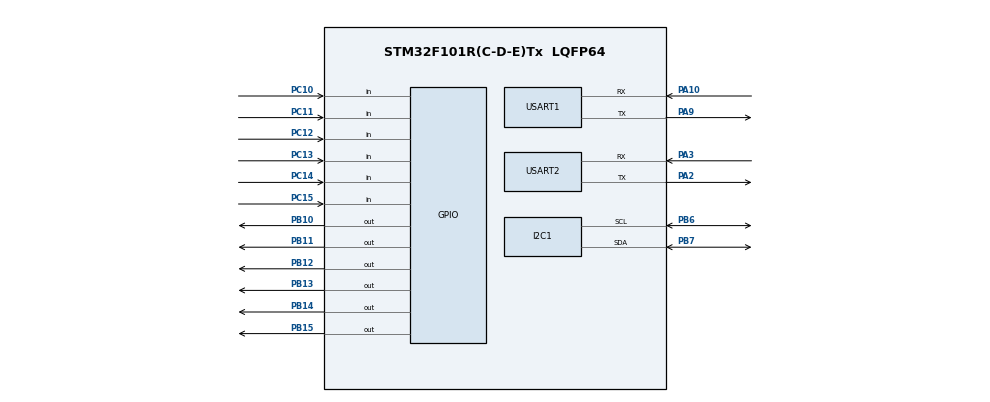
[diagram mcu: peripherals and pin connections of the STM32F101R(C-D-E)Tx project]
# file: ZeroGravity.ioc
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Mcu.Family=STM32F1
PD1-OSC_OUT.Mode=HSE-External-Oscillator
PA10.Mode=Asynchronous
PC10.Signal=GPIO_Input
PC11.Signal=GPIO_Input
PC12.Signal=GPIO_Input
PC13-TAMPER-RTC.Signal=GPIO_Input
PD0-OSC_IN.Signal=RCC_OSC_IN
PC14-OSC32_IN.Signal=GPIO_Input
PB11.Signal=GPIO_Output
PB15.Signal=GPIO_Output
PB13.Signal=GPIO_Output
ProjectManager.StackSize=0x400
PD1-OSC_OUT.Signal=RCC_OSC_OUT
PA13.Signal=SYS_JTMS-SWDIO
PA3.Mode=Asynchronous
PA9.Mode=Asynchronous
ProjectManager.TargetToolchain=STM32CubeIDE
PA9.Signal=USART1_TX
PB6.Signal=I2C1_SCL
PB6.Mode=I2C
PC15-OSC32_OUT.Signal=GPIO_Input
PB10.Signal=GPIO_Output
PD0-OSC_IN.Mode=HSE-External-Oscillator
PB14.Signal=GPIO_Output
board=custom
RCC.APB2Freq_Value=8000000
PA14.Mode=Serial_Wire
PB7.Signal=I2C1_SDA
PA13.Mode=Serial_Wire
Mcu.Name=STM32F101R(C-D-E)Tx
PA2.Signal=USART2_TX
Mcu.Package=LQFP64
USART2.VirtualMode=VM_ASYNC
USART1.VirtualMode=VM_ASYNC
PB7.Mode=I2C
PA10.Signal=USART1_RX
PA14.Signal=SYS_JTCK-SWCLK
ProjectManager.HeapSize=0x200
NVIC.PriorityGroup=NVIC_PRIORITYGROUP_4
PA2.Mode=Asynchronous
RCC.APB1Freq_Value=8000000
PB12.Signal=GPIO_Output
PA3.Signal=USART2_RX

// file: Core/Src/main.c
/* USER CODE BEGIN Header */
/**
  ******************************************************************************
  * @file           : main.c
  * @brief          : Main program body
  ******************************************************************************
  * @attention
  *
  * <h2><center>&copy; Copyright (c) 2021 STMicroelectronics.
  * All rights reserved.</center></h2>
  *
  * This software component is licensed by ST under BSD 3-Clause license,
  * the "License"; You may not use this file except in compliance with the
  * License. You may obtain a copy of the License at:
  *                        opensource.org/licenses/BSD-3-Clause
  *
  ******************************************************************************
  */
/* USER CODE END Header */
#include "main.h"
#include "i2c.h"
#include "usart.h"
#include "gpio.h"

/* USER CODE BEGIN Includes */
#include "sh1106.h"
/* USER CODE END Includes */

void SystemClock_Config(void);

int main(void)
{

  /* MCU Configuration--------------------------------------------------------*/

  /* Reset of all peripherals, Initializes the Flash interface and the Systick. */
  HAL_Init();

  /* Configure the system clock */
  SystemClock_Config();

  /* Initialize all configured peripherals */
  MX_GPIO_Init();
  MX_I2C1_Init();
  MX_USART1_UART_Init();
  MX_USART2_UART_Init();
  /* USER CODE BEGIN 2 */
  sh1106_Init();
  /* USER CODE END 2 */

  /* Infinite loop */
  while (1)
  {

    /* USER CODE BEGIN 3 */
	  //sh1106_test();
	  printf("Serial Test\r\n");
	  HAL_Delay(100);
  }
  /* USER CODE END 3 */
}

void SystemClock_Config(void)
{
  RCC_OscInitTypeDef RCC_OscInitStruct = {0};
  RCC_ClkInitTypeDef RCC_ClkInitStruct = {0};

  /** Initializes the RCC Oscillators according to the specified parameters
  * in the RCC_OscInitTypeDef structure.
  */
  RCC_OscInitStruct.OscillatorType = RCC_OSCILLATORTYPE_HSI;
  RCC_OscInitStruct.HSIState = RCC_HSI_ON;
  RCC_OscInitStruct.HSICalibrationValue = RCC_HSICALIBRATION_DEFAULT;
  RCC_OscInitStruct.PLL.PLLState = RCC_PLL_NONE;
  if (HAL_RCC_OscConfig(&RCC_OscInitStruct) != HAL_OK)
  {
    Error_Handler();
  }
  /** Initializes the CPU, AHB and APB buses clocks
  */
  RCC_ClkInitStruct.ClockType = RCC_CLOCKTYPE_HCLK|RCC_CLOCKTYPE_SYSCLK
                              |RCC_CLOCKTYPE_PCLK1|RCC_CLOCKTYPE_PCLK2;
  RCC_ClkInitStruct.SYSCLKSource = RCC_SYSCLKSOURCE_HSI;
  RCC_ClkInitStruct.AHBCLKDivider = RCC_SYSCLK_DIV1;
  RCC_ClkInitStruct.APB1CLKDivider = RCC_HCLK_DIV1;
  RCC_ClkInitStruct.APB2CLKDivider = RCC_HCLK_DIV1;

  if (HAL_RCC_ClockConfig(&RCC_ClkInitStruct, FLASH_LATENCY_0) != HAL_OK)
  {
    Error_Handler();
  }
}

void Error_Handler(void)
{
  __disable_irq();
  while (1)
  {
  }
}

/************************ (C) COPYRIGHT STMicroelectronics *****END OF FILE****/
